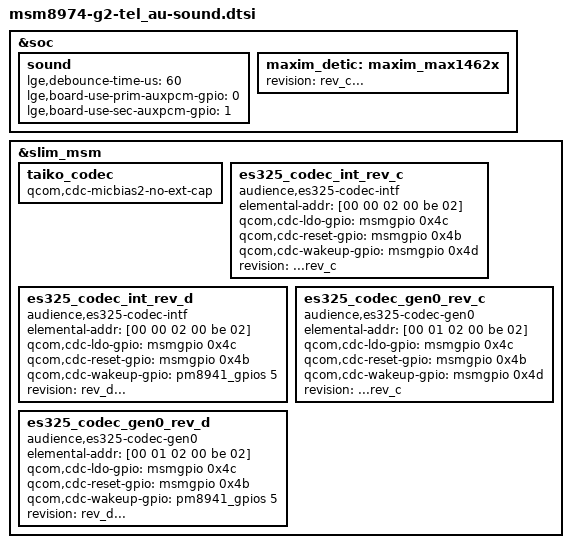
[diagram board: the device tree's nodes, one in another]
/* Copyright (c) 2013, LGE Electronics. All rights reserved.
 *
 * This program is free software; you can redistribute it and/or modify
 * it under the terms of the GNU General Public License version 2 and
 * only version 2 as published by the Free Software Foundation.
 *
 * This program is distributed in the hope that it will be useful,
 * but WITHOUT ANY WARRANTY; without even the implied warranty of
 * MERCHANTABILITY or FITNESS FOR A PARTICULAR PURPOSE.  See the
 * GNU General Public License for more details.
 */

&soc {

	sound {
		lge,debounce-time-us = <60>;
		lge,board-use-prim-auxpcm-gpio = <0>;
		lge,board-use-sec-auxpcm-gpio = <1>;
	};

	maxim_detic:maxim_max1462x {
		status = "ok";
		revision = "rev_c...";
	};

};

&slim_msm {

	taiko_codec {
		qcom,cdc-micbias2-no-ext-cap;
	};

	es325_codec_int_rev_c {
		status = "ok";
		compatible = "audience,es325-codec-intf";
		elemental-addr = [00 00 02 00 be 02];
		qcom,cdc-ldo-gpio = <&msmgpio 0x4c 0x0>;
		qcom,cdc-reset-gpio = <&msmgpio 0x4b 0x0>;
		qcom,cdc-wakeup-gpio = <&msmgpio 0x4d 0x0>;
		revision = "...rev_c";
	};

	es325_codec_int_rev_d {
		status = "ok";
		compatible = "audience,es325-codec-intf";
		elemental-addr = [00 00 02 00 be 02];
		qcom,cdc-ldo-gpio = <&msmgpio 0x4c 0x0>;
		qcom,cdc-reset-gpio = <&msmgpio 0x4b 0x0>;
		qcom,cdc-wakeup-gpio = <&pm8941_gpios 5 0x00>;
		revision = "rev_d...";
	};

	es325_codec_gen0_rev_c {
		status = "ok";
		compatible = "audience,es325-codec-gen0";
		elemental-addr = [00 01 02 00 be 02];
		qcom,cdc-ldo-gpio = <&msmgpio 0x4c 0x0>;
		qcom,cdc-reset-gpio = <&msmgpio 0x4b 0x0>;
		qcom,cdc-wakeup-gpio = <&msmgpio 0x4d 0x0>;
		revision = "...rev_c";
	};

	es325_codec_gen0_rev_d {
		status = "ok";
		compatible = "audience,es325-codec-gen0";
		elemental-addr = [00 01 02 00 be 02];
		qcom,cdc-ldo-gpio = <&msmgpio 0x4c 0x0>;
		qcom,cdc-reset-gpio = <&msmgpio 0x4b 0x0>;
		qcom,cdc-wakeup-gpio = <&pm8941_gpios 5 0x00>;
		revision = "rev_d...";
	};

};
